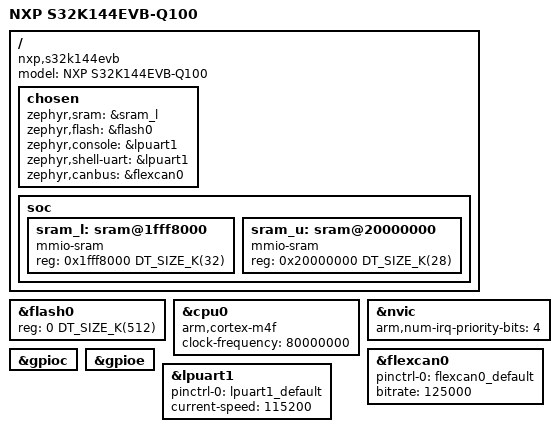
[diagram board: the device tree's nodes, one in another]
/*
 * Copyright (c) 2026 Maior Cristian-Alexandru
 * SPDX-License-Identifier: Apache-2.0
 */

/dts-v1/;
#include <zephyr/dt-bindings/gpio/gpio.h>
#include <dt-bindings/clock/nxp_s32k146_clock.h>
#include <arm/nxp/nxp_s32k146.dtsi>
#include "s32k144evb-pinctrl.dtsi"

/ {
	model = "NXP S32K144EVB-Q100";
	compatible = "nxp,s32k144evb";

	chosen {
		zephyr,sram = &sram_l;
		zephyr,flash = &flash0;
		zephyr,console = &lpuart1;
		zephyr,shell-uart = &lpuart1;
		zephyr,canbus = &flexcan0;
	};
};

/* S32K146 dtsi sizes memory for 128K SRAM / 1M flash; shrink to S32K144. */
/delete-node/ &sram_l;
/delete-node/ &sram_u;

/ {
	soc {
		sram_l: sram@1fff8000 {
			compatible = "mmio-sram";
			reg = <0x1fff8000 DT_SIZE_K(32)>;
		};

		sram_u: sram@20000000 {
			compatible = "mmio-sram";
			reg = <0x20000000 DT_SIZE_K(28)>;
		};
	};
};

&flash0 {
	reg = <0 DT_SIZE_K(512)>;
};

&cpu0 {
	compatible = "arm,cortex-m4f";
	clock-frequency = <80000000>;
};

&nvic {
	arm,num-irq-priority-bits = <4>;
};

&flexcan0 {
	pinctrl-0 = <&flexcan0_default>;
	pinctrl-names = "default";
	bitrate = <125000>;
	status = "okay";
};

&gpioc {
	status = "okay";
};

&gpioe {
	status = "okay";
};

&lpuart1 {
	pinctrl-0 = <&lpuart1_default>;
	pinctrl-names = "default";
	current-speed = <115200>;
	status = "okay";
};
